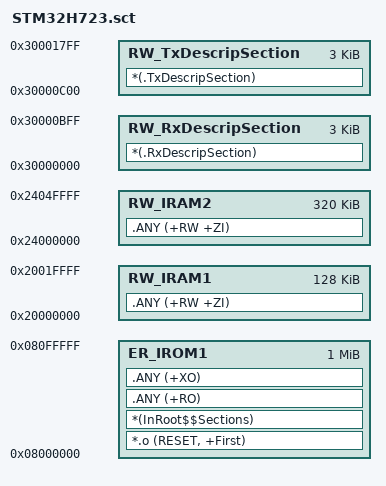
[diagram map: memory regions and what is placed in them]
; *************************************************************
; *** Scatter-Loading Description File generated by uVision ***
; *************************************************************

LR_IROM1 0x08000000 0x00100000  {    ; load region size_region
  ER_IROM1 0x08000000 0x00100000  {  ; load address = execution address
   *.o (RESET, +First)
   *(InRoot$$Sections)
   .ANY (+RO)
   .ANY (+XO)
  }
  RW_IRAM1 0x20000000 0x00020000  {  ; RW data
   .ANY (+RW +ZI)
  }
  RW_IRAM2 0x24000000 0x00050000  {
   .ANY (+RW +ZI)
  }
  
  RW_RxDescripSection 0x30000000 0xC00  {
   *(.RxDescripSection)
  }

  RW_TxDescripSection 0x30000C00 0xC00  {
   *(.TxDescripSection)
  }

;  RW_NXDriverSection 0x24000000 0x10000  {
;   *(.NetXPoolSection)
;  }
  
;  RW_SocketSection 0x20000000 0x8000 {
;	*(.SocketSection)
;  }
}

